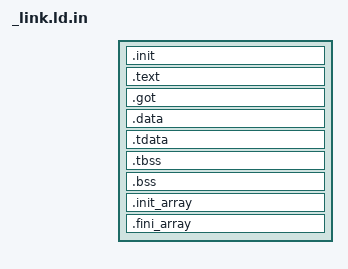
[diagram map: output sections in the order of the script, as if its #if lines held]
ENTRY(_start)

PHDRS {
	text PT_LOAD FILEHDR PHDRS FLAGS(5);
	data PT_LOAD FLAGS(6);
	tls PT_TLS;
}

SECTIONS {
#ifdef SHLIB
	. = SEGMENT_START("text-segment", 0);
#else
	. = SEGMENT_START("text-segment", 0x400000);
	PROVIDE (__executable_start = .);
#endif
	. = . + SIZEOF_HEADERS;

	/* Workaround proper alignment of the .init section */
	. = ALIGN(., 16);

	.init : {
		*(.init);
	} :text

	.text : {
		*(.text .text.*);
		*(.rodata .rodata.*);
	} :text

	. = . + 0x4000;

	.got : {
		/* Tell the linker where we expect GP to point. */
		__gp = .;
		*(.got .got.*);
	} :data

	.data : {
		*(.opd);
		*(.data .data.*);
		*(.sdata);
		*(.sdata.*);
	} :data

	.tdata : {
		*(.tdata);
		*(.tdata.*);
		*(.gnu.linkonce.td.*);
	} :data :tls

	.tbss : {
		*(.tbss);
		*(.tbss.*);
		*(.gnu.linkonce.tb.*);
	} :data :tls

	.bss : {
		*(.sbss);
		*(.scommon);
		*(COMMON);
		*(.bss);
	} :data

	__dso_handle = .;

	.init_array : {
#ifndef SHLIB
		PROVIDE_HIDDEN (__init_array_start = .);
#endif
		KEEP (*(SORT_BY_INIT_PRIORITY(.init_array.*) SORT_BY_INIT_PRIORITY(.ctors.*)))
		KEEP (*(.init_array .ctors))
#ifndef SHLIB
		PROVIDE_HIDDEN (__init_array_end = .);
#endif
	}

	.fini_array : {
#ifndef SHLIB
		PROVIDE_HIDDEN (__fini_array_start = .);
#endif
		KEEP (*(SORT_BY_INIT_PRIORITY(.fini_array.*) SORT_BY_INIT_PRIORITY(.dtors.*)))
		KEEP (*(.fini_array .dtors))
#ifndef SHLIB
		PROVIDE_HIDDEN (__fini_array_end = .);
#endif
	}

	_end = .;

	/DISCARD/ : {
		*(*);
	}
}
